# ATmega1608 register map
Vendor: Atmel; File version: 1.0
CPU: other r0p0, little endian, no MPU, no FPU, 4 interrupt priority bits
Registers are 8-bit, read-write, reset 0x0 unless marked. A register's access mark holds for its fields unless they carry their own. Offsets are from the block's base; [hi:lo] are bit positions; {n}, {i} and the like mark numbered series.

## GPIO — General Purpose IO
Base 0x0080001C
{0x0+i} GPIOR{i} (i=0..3) — General Purpose IO Register {i}

## LOCKBIT
Base 0x0080128A
0x00 LOCKBIT — Lock Bits
  [7:0] LB
    58=RWLOCK (Read and write lock); 197=NOLOCK (No locks)

## NVMCTRL — Non-volatile Memory Controller
Base 0x00801000
0x00 CTRLA — Control A
  [2:0] CMD — Command
    0=NONE (No Command); 1=PAGEWRITE (Write page); 2=PAGEERASE (Erase page); 3=PAGEERASEWRITE (Erase and write page); 4=PAGEBUFCLR (Page buffer clear); 5=CHIPERASE; 6=EEERASE (EEPROM erase); 7=FUSEWRITE (Write fuse (PDI only))
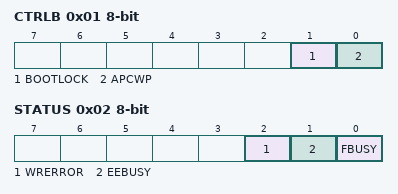
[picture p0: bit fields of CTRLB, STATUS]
0x01 CTRLB — Control B
  [1] BOOTLOCK
  [0] APCWP — Application code write protect
0x02 STATUS ro
  [2] WRERROR — Write error
  [1] EEBUSY — EEPROM busy
  [0] FBUSY — Flash busy
0x03 INTCTRL — Interrupt Control
  [0] EEREADY — EEPROM Ready
0x04 INTFLAGS — Interrupt Flags
  [0] EEREADY — EEPROM Ready
0x06 DATA 16-bit (reset mask 0xFF)
0x08 ADDR 16-bit (reset mask 0xFF) — Address

## PORTA — I/O Ports
Base 0x00800400
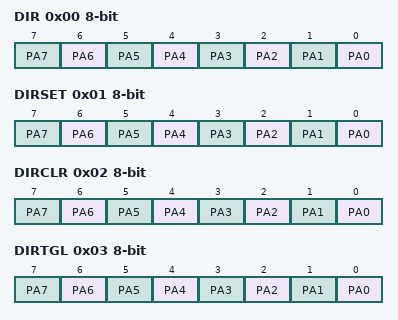
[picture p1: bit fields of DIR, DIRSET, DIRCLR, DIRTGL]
0x00 DIR — Data Direction
  [n] PA{n} (n=0..7) — Pin A{n}
0x01 DIRSET — Data Direction Set
  [n] PA{n} (n=0..7) — Pin A{n}
0x02 DIRCLR — Data Direction Clear
  [n] PA{n} (n=0..7) — Pin A{n}
0x03 DIRTGL — Data Direction Toggle
  [n] PA{n} (n=0..7) — Pin A{n}
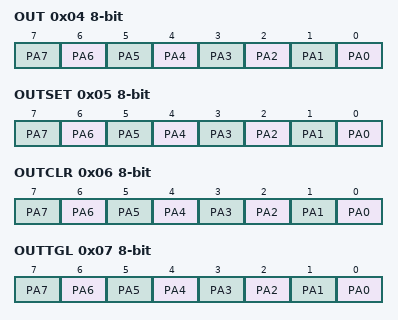
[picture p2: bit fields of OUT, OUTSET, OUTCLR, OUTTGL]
0x04 OUT — Output Value
  [n] PA{n} (n=0..7) — Pin A{n}
0x05 OUTSET — Output Value Set
  [n] PA{n} (n=0..7) — Pin A{n}
0x06 OUTCLR — Output Value Clear
  [n] PA{n} (n=0..7) — Pin A{n}
0x07 OUTTGL — Output Value Toggle
  [n] PA{n} (n=0..7) — Pin A{n}
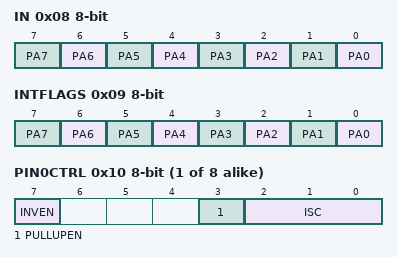
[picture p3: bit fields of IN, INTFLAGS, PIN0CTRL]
0x08 IN — Input Value
  [n] PA{n} (n=0..7) — Pin A{n}
0x09 INTFLAGS — Interrupt Flags
  [n] PA{n} (n=0..7) — Pin A{n}
0x0A PORTCTRL — Port Control
  [0] SRL — Slew Rate Limit Enable
{0x10+i} PIN{i}CTRL (i=0..7) — Pin {i} Control
  [7] INVEN — Inverted I/O Enable
  [3] PULLUPEN — Pullup enable
  [2:0] ISC — Input/Sense Configuration
    0=INTDISABLE (Interrupt disabled but input buffer enabled); 1=BOTHEDGES (Sense Both Edges); 2=RISING (Sense Rising Edge); 3=FALLING (Sense Falling Edge); 4=INPUT_DISABLE (Digital Input Buffer disabled); 5=LEVEL (Sense low Level)

## PORTB — I/O Ports
Base 0x00800420
Same registers: PORTD 0x00800460, PORTE 0x00800480, PORTF 0x008004A0
Registers as PORTA; these are added or differ:
0x00 DIR — Data Direction
0x01 DIRSET — Data Direction Set
0x02 DIRCLR — Data Direction Clear
0x03 DIRTGL — Data Direction Toggle
0x04 OUT — Output Value
0x05 OUTSET — Output Value Set
0x06 OUTCLR — Output Value Clear
0x07 OUTTGL — Output Value Toggle
0x08 IN — Input Value
0x09 INTFLAGS — Interrupt Flags
  [7:0] INT — Pin Interrupt

## PORTC — I/O Ports
Base 0x00800440
Registers as PORTB, without PORTCTRL; these are added or differ:
0x0A PORTCTRL — Port Control
  [0] SRL — Slew Rate Limit Enable

## PORTMUX — Port Multiplexer
Base 0x008005E0
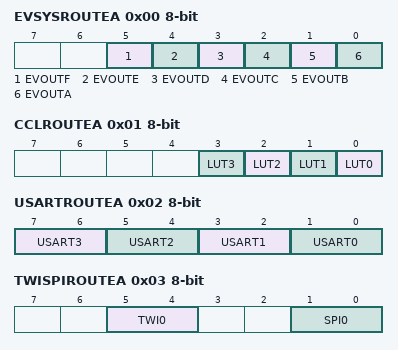
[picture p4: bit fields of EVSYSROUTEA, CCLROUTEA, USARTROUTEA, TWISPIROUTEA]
0x00 EVSYSROUTEA — Port Multiplexer EVSYS
  [5] EVOUTF — Event Output F
    0=DEFAULT (EVOUT on PF2)
  [4] EVOUTE — Event Output E
    0=DEFAULT (EVOUT on PE2)
  [3] EVOUTD — Event Output D
    0=DEFAULT (EVOUT on PD2); 1=ALT1 (EVOUT on PD7)
  [2] EVOUTC — Event Output C
    0=DEFAULT (EVOUT on PC2)
  [1] EVOUTB — Event Output B
    0=DEFAULT (EVOUT on PB2)
  [0] EVOUTA — Event Output A
    0=DEFAULT (EVOUT on PA2); 1=ALT1 (EVOUT on PA7)
0x01 CCLROUTEA — Port Multiplexer CCL
  [n] LUT{n} (n=0..3) — CCL LUT{n}
0x02 USARTROUTEA — Port Multiplexer USART register A
  [7:6] USART3 — Port Multiplexer USART3
    0=DEFAULT (USART3 on PB[3:0]); 1=ALT1 (USART3 on PB[5:4]); 3=NONE (Not connected to any pins)
  [5:4] USART2 — Port Multiplexer USART2
    0=DEFAULT (USART2 on PF[3:0]); 1=ALT1 (USART2 on PF[6:4]); 3=NONE (Not connected to any pins)
  [3:2] USART1 — Port Multiplexer USART1
    0=DEFAULT (USART1 on PC[3:0]); 1=ALT1 (USART1 on PC[7:4]); 3=NONE (Not connected to any pins)
  [1:0] USART0 — Port Multiplexer USART0
    0=DEFAULT (USART0 on PA[3:0]); 1=ALT1 (USART0 on PA[7:4]); 3=NONE (Not connected to any pins)
0x03 TWISPIROUTEA — Port Multiplexer TWI and SPI
  [5:4] TWI0 — Port Multiplexer TWI0
    0=DEFAULT (SCL/SDA on PA[3:2], Client mode on PC[3:2] in dual TWI mode); 1=ALT1 (SCL/SDA on PA[3:2], Client mode on PF[3:2] in dual TWI mode); 2=ALT2 (SCL/SDA on PC[3:2], Client mode on PF[3:2] in dual TWI mode); 3=NONE (Not connected to any pins)
  [1:0] SPI0 — Port Multiplexer SPI0
    0=DEFAULT (SPI0 on PA[7:4]); 1=ALT1 (SPI0 on PC[3:0]); 2=ALT2 (SPI0 on PE[3:0]); 3=NONE (Not connected to any pins)
0x04 TCAROUTEA — Port Multiplexer TCA
  [2:0] TCA0 — Port Multiplexer TCA0
    0=PORTA (TCA0 pins on PA[5:0]); 1=PORTB (TCA0 pins on PB[5:0]); 2=PORTC (TCA0 pins on PC[5:0]); 3=PORTD (TCA0 pins on PD[5:0]); 4=PORTE (TCA0 pins on PE[5:0]); 5=PORTF (TCA0 pins on PF[5:0])
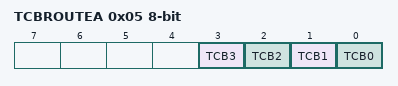
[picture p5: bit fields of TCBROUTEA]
0x05 TCBROUTEA — Port Multiplexer TCB
  [3] TCB3 — Port Multiplexer TCB3
    1=ALT1 (WO on PC1)
  [2] TCB2 — Port Multiplexer TCB2
    0=DEFAULT (WO on PC0)
  [1] TCB1 — Port Multiplexer TCB1
    0=DEFAULT (WO on PA3); 1=ALT1 (WO on PF5)
  [0] TCB0 — Port Multiplexer TCB0
    0=DEFAULT (WO on PA2); 1=ALT1 (WO on PF4)
